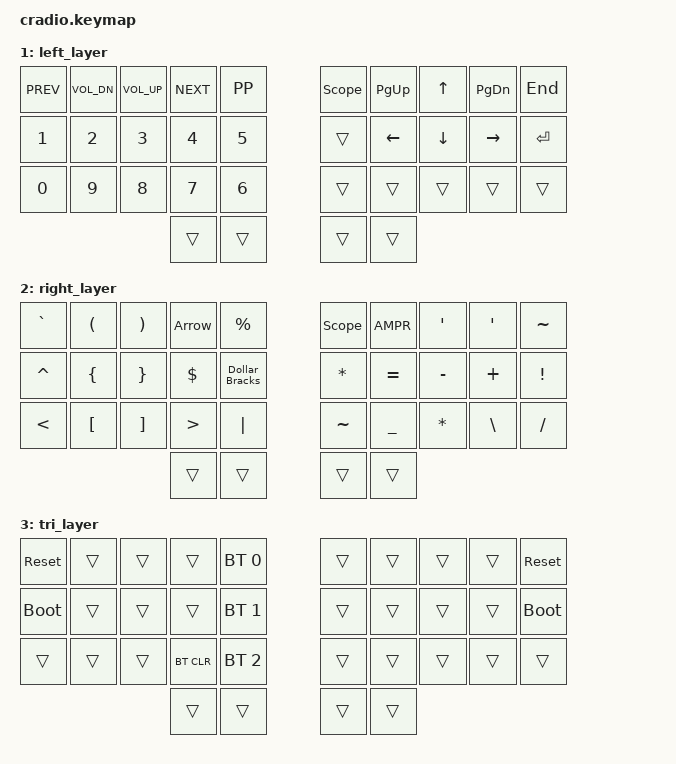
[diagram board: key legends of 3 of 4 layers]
#include <behaviors.dtsi>
#include <dt-bindings/zmk/keys.h>
#include <dt-bindings/zmk/bt.h>
#include "34keys.h"

/ {
    behaviors {
        #include "behaviorsfs.dtsi"
    };

    conditional_layers {
        compatible = "zmk,conditional-layers";
        tri_layer {
            if-layers = <1 2>;
            then-layer = <3>;
        };
    };

    combos {
        #include "combos.dtsi"
    };

    macros {
        #include "macros.dtsi"
    };

    keymap {
        compatible = "zmk,keymap";

        default_layer {
            bindings = <
        //╭──────────┬──────────┬──────────┬──────────┬──────────╮   ╭──────────┬──────────┬──────────┬──────────┬──────────╮
        //│  B       │  L       │  D       │  C       │  V       │   │  J       │  F       │  O       │  U       │ ' "      │
            &kp B      &kp L      &kp D      &kp C      &kp V         &kp J      &kp F      &kp O      &kp U      &kp SQT
        //├──────────┼──────────┼──────────┼──────────┼───── ────┤   ├──────────┼──────────┼──────────┼──────────┼──────────┤
        //│  N       │  R       │  S       │  T       │  G       │   │  Y       │  H       │  A       │  E       │  I       │
            HRML(N,        R,         S,         T)     &kp G          &kp Y      HRMR(H,        A,         E,        I)
        //├──────────┼──────────┼──────────┼──────────┼────── ───┤   ├──────────┼──────────┼──────────┼──────────┼──────────┤
        //│  X       │  Q       │  M       │  W        │  Z      │   │  K       │  M       │ , <      │ . >      │ / ?      │
            &kp X      &kp Q      &kp M      &kp W      &kp Z          &kp K      &kp P      &kp COMMA  &kp DOT    &kp FSLH
        //╰──────────┴──────────┴─────────┼─────────── ┼─────────┤  ├─────────────────────┼──────────┴──────────┴──────────╯
                                           &lt NAV DEL  &kp ENTER     &kp SPACE    &lt SYM BSPC
        //                                ╰────────────┴──────────╯  ╰────────────┴────────────────╯
            >;
        };

        left_layer {
            bindings = <
        //╭────────── ┬─────────  ─┬────────   ─┬──────────┬──────────╮   ╭──────────┬──────────┬──────────┬──────────┬──────────╮
        //│ INSERT    │            │            │          │          │   │ HOME     │ PAGE DN  │ PAGE UP  │ END      │  :       │
           &kp K_PREV  &kp K_VOL_DN &kp K_VOL_UP &kp K_NEXT  &kp K_PP       &Scope    &kp PG_UP   &kp UP    &kp PG_DN   &kp END  
        //├────────── ┼───────  ───┼───────   ──┼──────────┼──────────┤   ├──────────┼──────────┼──────────┼──────────┼──────────┤
        //│ 1         │  2         │  3         │  4       │  5       │   │ LEFT     │ DOWN     │ UP       │ RIGHT    │  ENT     │
            &kp N1     &kp N2        &kp N3      &kp N4     &kp N5          &trans    &kp LEFT    &kp DOWN   &kp RIGHT  &kp RET
        //├──────── ──┼── ─── ─────┼────────  ──┼──────────┼──────────┤   ├──────────┼──────────┼──────────┼──────────┼──────────┤
        //│ 0         │  9         │  8         │  7       │  6       │   │          │          │          │          │          │
            &kp N0     &kp N9        &kp N8      &kp N7     &kp N6         &trans     &trans     &trans     &trans     &trans
        //╰────────── ┴─────────  ─┴──────────┼──────────┼──────────┤   ├──────────┼──────────┼──────────┴──────────┴──────────╯
                                               &trans      &trans        &trans     &trans
           //                                 ╰──────────┴──────────╯   ╰──────────┴──────────╯
            >;
        };

        right_layer {
            bindings = <
        //╭──────────┬──────────┬──────────┬──────────┬──────────╮   ╭──────────┬──────────┬──────────┬──────────┬──────────╮
        //│   `      │  [       │  {       │  =>      │  %       │   │  :=       │  &      │  '       │  "       │  @       │
           &kp GRAVE &kp LPAR &kp RPAR &Arrow &kp PRCNT                 &kp Scope    &kp AMPR &kp APOS &kp QUOT &kp TILDE                              //├──────────┼──────────┼──────────┼──────────┼──────────┤   ├──────────┼──────────┼──────────┼──────────┼──────────┤
        //│  ^       │  @       │  #       │  $       │  ${}     │   │  *       │  =       │  -       │  +       │  !     │
            &kp CARET &kp LBRC   &kp RBRC   &kp DLLR   &Dollar_Bracks &kp ASTRK  &kp EQUAL  &kp MINUS  &kp PLUS   &kp EXCL
        //├──────────┼──────────┼──────────┼──────────┼──────────┤   ├──────────┼──────────┼──────────┼──────────┼──────────┤
        //│  <        │  [       │   ]      │   >     │  |       │   │  &       │  _       │  +       │  \       │  /       │
            &kp LT      &kp LBKT   &kp RBKT   &kp GT     &kp PIPE           &kp TILDE &kp UNDER  &kp STAR   &kp BSLH   &kp FSLH
        //╰──────────┴──────────┴──────────┼──────────┼──────────┤   ├──────────┼──────────┼──────────┴──────────┴──────────╯
                                             &trans     &trans         &trans     &trans
        //                                 ╰──────────┴──────────╯   ╰──────────┴──────────╯
            >;
        };

        tri_layer {
            bindings = <
        //╭──────────┬──────────┬──────────┬──────────┬──────────╮   ╭──────────┬──────────┬──────────┬──────────┬──────────╮
        //│ RESET    │          │          │          │PROFILE 0 │   │          │          │          │          │  RESET   │
           &sys_reset  &trans     &trans     &trans    &bt BT_SEL 0    &trans     &trans     &trans     &trans    &sys_reset
        //├──────────┼──────────┼──────────┼──────────┼──────────┤   ├──────────┼──────────┼──────────┼──────────┼──────────┤
        //│BOOTLOADER│          │          │          │PROFILE 1 │   │          │          │          │          │BOOTLOADER│
          &bootloader  &trans     &trans     &trans    &bt BT_SEL 1    &trans     &trans     &trans     &trans    &bootloader
        //├──────────┼──────────┼──────────┼──────────┼──────────┤   ├──────────┼──────────┼──────────┼──────────┼──────────┤
        //│          │          │          │ CLEAR BT │PROFILE 2 │   │          │          │          │          │          │
            &trans     &trans     &trans    &bt BT_CLR &bt BT_SEL 2    &trans     &trans     &trans     &trans     &trans
        //╰──────────┴──────────┴──────────┼──────────┼──────────┤   ├──────────┼──────────┼──────────┴──────────┴──────────╯
                                             &trans     &trans         &trans     &trans
        //                                 ╰──────────┴──────────╯   ╰──────────┴──────────╯
            >;
        };
    };
};
